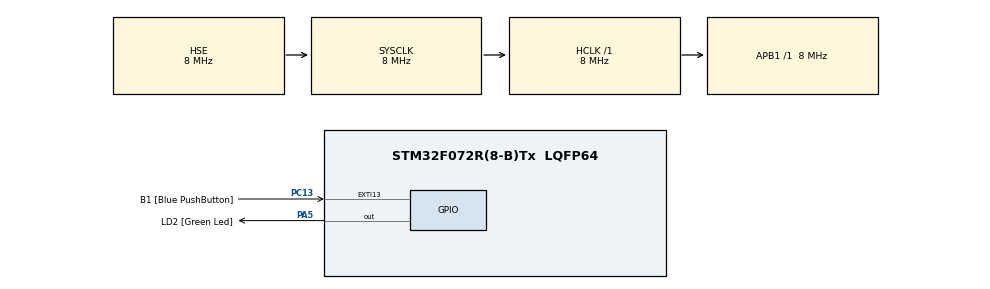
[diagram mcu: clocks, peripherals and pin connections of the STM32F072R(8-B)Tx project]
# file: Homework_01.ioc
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FREERTOS.Tasks01=myTask01,2,128,Task1_Handler,Default,NULL,Dynamic,NULL,NULL;myTask02,3,128,Task2_Handler,Default,NULL,Dynamic,NULL,NULL
Mcu.Family=STM32F0
Mcu.Name=STM32F072R(8-B)Tx
Mcu.Package=LQFP64
NVIC.EXTI4_15_IRQn=true\:3\:0\:false\:false\:true\:true\:true\:true\:true
PA13.GPIO_Label=TMS
PA13.Mode=Serial_Wire
PA13.Signal=SYS_SWDIO
PA14.GPIO_Label=TCK
PA14.Mode=Serial_Wire
PA14.Signal=SYS_SWCLK
PA5.GPIO_Label=LD2 [Green Led]
PA5.GPIO_Mode=GPIO_MODE_OUTPUT_PP
PA5.GPIO_PuPd=GPIO_NOPULL
PA5.GPIO_Speed=GPIO_SPEED_FREQ_LOW
PA5.Signal=GPIO_Output
PC13.GPIO_Label=B1 [Blue PushButton]
PC13.GPIO_ModeDefaultEXTI=GPIO_MODE_IT_FALLING
PC13.Signal=GPXTI13
PC14-OSC32_IN.Signal=RCC_OSC32_IN
PC15-OSC32_OUT.Signal=RCC_OSC32_OUT
PF0-OSC_IN.Mode=HSE-External-Oscillator
PF0-OSC_IN.Signal=RCC_OSC_IN
PF1-OSC_OUT.Mode=HSE-External-Oscillator
PF1-OSC_OUT.Signal=RCC_OSC_OUT
ProjectManager.HeapSize=0x200
ProjectManager.StackSize=0x400
ProjectManager.TargetToolchain=STM32CubeIDE
RCC.AHBFreq_Value=8000000
RCC.APB1Freq_Value=8000000
RCC.APB1TimFreq_Value=8000000
RCC.FLatency-AdvancedSettings=FLASH_LATENCY_0
RCC.HCLKFreq_Value=8000000
RCC.PLLDivider=RCC_PREDIV_DIV2
RCC.PLLMUL=RCC_PLL_MUL12
RCC.PREFETCH_ENABLE-AdvancedSettings=1
RCC.SYSCLKFreq_VALUE=8000000
RCC.SYSCLKSource=RCC_SYSCLKSOURCE_HSE
VP_FREERTOS_VS_CMSIS_V1.Mode=CMSIS_V1
board=NUCLEO-F072RB

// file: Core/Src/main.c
/* USER CODE BEGIN Header */
/**
  ******************************************************************************
  * @file           : main.c
  * @brief          : Main program body
  ******************************************************************************
  * @attention
  *
  * Copyright (c) 2024 STMicroelectronics.
  * All rights reserved.
  *
  * This software is licensed under terms that can be found in the LICENSE file
  * in the root directory of this software component.
  * If no LICENSE file comes with this software, it is provided AS-IS.
  *
  ******************************************************************************
  */
/* USER CODE END Header */
#include "main.h"
#include "cmsis_os.h"

osThreadId myTask01Handle;
osThreadId myTask02Handle;

void SystemClock_Config(void);
static void MX_GPIO_Init(void);
void Task1_Handler(void const * argument);
void Task2_Handler(void const * argument);

/* USER CODE BEGIN 0 */
uint8_t buttonState = 0;
/* USER CODE END 0 */

int main(void)
{

  /* MCU Configuration--------------------------------------------------------*/

  /* Reset of all peripherals, Initializes the Flash interface and the Systick. */
  HAL_Init();

  /* Configure the system clock */
  SystemClock_Config();

  /* Initialize all configured peripherals */
  MX_GPIO_Init();

  /* Create the thread(s) */
  /* definition and creation of myTask01 */
  osThreadDef(myTask01, Task1_Handler, osPriorityHigh, 0, 128);
  myTask01Handle = osThreadCreate(osThread(myTask01), NULL);

  /* definition and creation of myTask02 */
  osThreadDef(myTask02, Task2_Handler, osPriorityRealtime, 0, 128);
  myTask02Handle = osThreadCreate(osThread(myTask02), NULL);

  /* Start scheduler */
  osKernelStart();
  /* We should never get here as control is now taken by the scheduler */
  /* Infinite loop */
  while (1)
  {

  }
}

void SystemClock_Config(void)
{
  RCC_OscInitTypeDef RCC_OscInitStruct = {0};
  RCC_ClkInitTypeDef RCC_ClkInitStruct = {0};

  /** Initializes the RCC Oscillators according to the specified parameters
  * in the RCC_OscInitTypeDef structure.
  */
  RCC_OscInitStruct.OscillatorType = RCC_OSCILLATORTYPE_HSE;
  RCC_OscInitStruct.HSEState = RCC_HSE_ON;
  RCC_OscInitStruct.PLL.PLLState = RCC_PLL_NONE;
  if (HAL_RCC_OscConfig(&RCC_OscInitStruct) != HAL_OK)
  {
    Error_Handler();
  }

  /** Initializes the CPU, AHB and APB buses clocks
  */
  RCC_ClkInitStruct.ClockType = RCC_CLOCKTYPE_HCLK|RCC_CLOCKTYPE_SYSCLK
                              |RCC_CLOCKTYPE_PCLK1;
  RCC_ClkInitStruct.SYSCLKSource = RCC_SYSCLKSOURCE_HSE;
  RCC_ClkInitStruct.AHBCLKDivider = RCC_SYSCLK_DIV1;
  RCC_ClkInitStruct.APB1CLKDivider = RCC_HCLK_DIV1;

  if (HAL_RCC_ClockConfig(&RCC_ClkInitStruct, FLASH_LATENCY_0) != HAL_OK)
  {
    Error_Handler();
  }
}

static void MX_GPIO_Init(void)
{
  GPIO_InitTypeDef GPIO_InitStruct = {0};

  /* GPIO Ports Clock Enable */
  __HAL_RCC_GPIOC_CLK_ENABLE();
  __HAL_RCC_GPIOF_CLK_ENABLE();
  __HAL_RCC_GPIOA_CLK_ENABLE();

  /*Configure GPIO pin Output Level */
  HAL_GPIO_WritePin(LD2_GPIO_Port, LD2_Pin, GPIO_PIN_RESET);

  /*Configure GPIO pin : B1_Pin */
  GPIO_InitStruct.Pin = B1_Pin;
  GPIO_InitStruct.Mode = GPIO_MODE_IT_FALLING;
  GPIO_InitStruct.Pull = GPIO_NOPULL;
  HAL_GPIO_Init(B1_GPIO_Port, &GPIO_InitStruct);

  /*Configure GPIO pin : LD2_Pin */
  GPIO_InitStruct.Pin = LD2_Pin;
  GPIO_InitStruct.Mode = GPIO_MODE_OUTPUT_PP;
  GPIO_InitStruct.Pull = GPIO_NOPULL;
  GPIO_InitStruct.Speed = GPIO_SPEED_FREQ_LOW;
  HAL_GPIO_Init(LD2_GPIO_Port, &GPIO_InitStruct);

  /* EXTI interrupt init*/
  HAL_NVIC_SetPriority(EXTI4_15_IRQn, 3, 0);
  HAL_NVIC_EnableIRQ(EXTI4_15_IRQn);

}

void Task1_Handler(void const * argument)
{
  /* USER CODE BEGIN 5 */
  /* Infinite loop */
	osPriority p1,p2;

  for(;;)
  {
	 HAL_GPIO_WritePin(GPIOA, GPIO_PIN_5, 1);
	 HAL_Delay(250);
	 HAL_GPIO_WritePin(GPIOA, GPIO_PIN_5, 0);
	 HAL_Delay(250);

	  if(buttonState == 1)
	  {
		  buttonState = 0;

		  p1 = osThreadGetPriority(myTask01Handle);
		  p2 = osThreadGetPriority(myTask02Handle) ;

		  osThreadSetPriority(myTask01Handle, p2);
		  osThreadSetPriority(myTask02Handle, p1);
	  }
  }
  /* USER CODE END 5 */
}

void Task2_Handler(void const * argument)
{
  /* USER CODE BEGIN Task2_Handler */
  /* Infinite loop */
	osPriority p1,p2;

  for(;;)
  {
    HAL_GPIO_WritePin(GPIOA, GPIO_PIN_5, 1);
    HAL_Delay(1000);
    HAL_GPIO_WritePin(GPIOA, GPIO_PIN_5, 0);
    HAL_Delay(1000);

    if(buttonState == 1)
    {
    	buttonState=0;

    	p1 = osThreadGetPriority(myTask01Handle);
    	p2 = osThreadGetPriority(myTask02Handle);

    	osThreadSetPriority(myTask01Handle, p2);
    	osThreadSetPriority(myTask02Handle, p1);

    }

  }
  /* USER CODE END Task2_Handler */
}

void Error_Handler(void)
{
  __disable_irq();
  while (1)
  {
  }
}
